# IMM100A register map
Vendor: Infineon; File version: 0.8.0 (Reference Manual v0.8.0)
CPU: CM0 r0p0, little endian, no MPU, no FPU, 2 interrupt priority bits
Registers are 32-bit, read-write, reset 0x0 unless marked. A register's access mark holds for its fields unless they carry their own. Offsets are from the block's base; [hi:lo] are bit positions; {n}, {i} and the like mark numbered series; <NAME> marks a mode.

## SCU_ANALOG — System Control Unit
Base 0x40011000
0x24 ANATSECTRL 16-bit — Temperature Sensor Control Register
  [0] TSE_EN — Temperature sensor enable
    0=Temperature sensor is disabled; 1=Temperature sensor is switched on
0x30 ANATSEIH 16-bit — Temperature Sensor High Temperature Interrupt Register
  [15:0] TSE_IH — Counter value for high temperature interrupt
0x34 ANATSEIL 16-bit reset 0xFFFF — Temperature Sensor Low Temperature Interrupt Register
  [15:0] TSE_IL — Counter value for low temperature interrupt
0x40 ANATSEMON 16-bit ro — Temperature Sensor Counter2 Monitor Register
  [15:0] TSE_MON — Result values; loaded by TSE_DONE
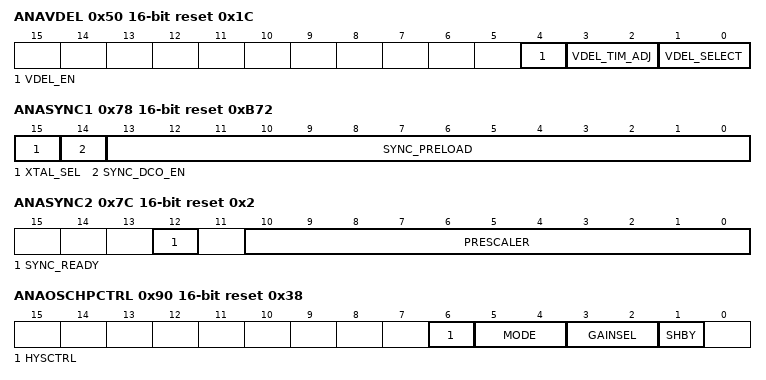
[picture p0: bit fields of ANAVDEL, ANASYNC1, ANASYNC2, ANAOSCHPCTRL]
0x50 ANAVDEL 16-bit reset 0x1C — Voltage Detector Control Register
  [4] VDEL_EN — VDEL unit Enable
    0=VDEL is disabled; 1=VDEL is active
  [3:2] VDEL_TIM_ADJ — VDEL Timing Setting
    0=typ 1us - slowest response time; 1=typ 500n; 2=typ 250n; 3=no delay - fastest response time
  [1:0] VDEL_SELECT — VDEL Range Select
    0=2.25V; 1=3.0V; 2=4.4V
0x6C ANAOFFSET 16-bit reset 0x40 — DCO1 Offset Register
  [6:0] ADJL_OFFSET
    0=- 3.xx%, typ; 63=DCO1 ADJL value is reduced by 1 step (DCO_ADJL - 1); 64=0, DCO_ADJL is not changed, default; 65=DCO1 ADJL value is increased by 1 step (DCO_ADJL + 1); 127=+ 3.xx%, typ
0x78 ANASYNC1 16-bit reset 0xB72 — DCO1 Sync Control Register 1
  [15] XTAL_SEL — Oscillator Source select
    0=OSC_LP is selected; 1=OSC_HP is selected
  [14] SYNC_DCO_EN — DCO1 synchronization feature enable
    0=No DCO1 synchronization via an external clock source. This option is used for the DCO1 calibration using the temperature sensor.; 1=DCO1 gets synchronized via an external clock source
  [13:0] SYNC_PRELOAD — Counter target value, which defines the update cycle
    0x1FFF=Longest integration time = best accuracy
0x7C ANASYNC2 16-bit access per field reset 0x2 — DCO1 Sync Control Register 2
  [12] SYNC_READY ro — DCO1 frequency reached its target value
    0=Actual DCO1 frequency is out of targe; 1=DCO1 is synchronized to the XTAL frequency
  [10:0] PRESCALER rw — Prescaler value
    0=Bypass: Internal sync counter frequency = crystal frequency; 1=DIV1: Internal sync counter feed freq. = crystal frequency/1; 2=DIV2: Internal sync counter feed freq. = crystal frequency/2; 0x7FF=Maximum divider value (for best accuracy, but slowest response)
0x8C ANAOSCLPCTRL 16-bit reset 0x3 — OSC_LP Control Register
  [1:0] MODE — OSC_LP Oscillator Mode
    0=Oscillator is enabled and in operation mode (OSC mode); 1=Oscillator is enabled, shaper is bypassed; 2=Oscillator is in power down mode; 3=Oscillator is in power down mode , Pad can be used in GPIO mode
0x90 ANAOSCHPCTRL 16-bit reset 0x38 — OSC_HP Control Register
  [6] HYSCTRL — Shaper Hystersis Mode
    0=External clock frequency < 20MHz; 1=External clock frequency > 20MHz
  [5:4] MODE — OSC_HP Oscillator Mode
    0=Oscillator is enabled and in active power mode with shaper enabled (OSC mode); 1=Oscillator in power down mode with shaper enabled (External Clock Input Mode); 2=Oscillator is enabled with shaper disabled. No clock output is available unless the shaper is bypass (SHBY=1); 3=Oscillator is in power down mode with shaper disabled. Pad can be used in GPIO mode.
  [3:2] GAINSEL — OSC_HP Oscillator Gain Selection
    0=Gain control is configured for frequencies from 4 MHz to y1 MHz; 1=Gain control is configured for frequencies from 4 MHz to y2 MHz; 2=Gain control is configured for frequencies from 4 MHz to 20 MHz
  [1] SHBY — Shaper Bypass Mode
    0=The shaper is not bypassed; 1=The shaper is bypassed

## CCU40 — Capture Compare Unit 4 - Unit 0
Base 0x48040000
Same registers: CCU41 0x48044000
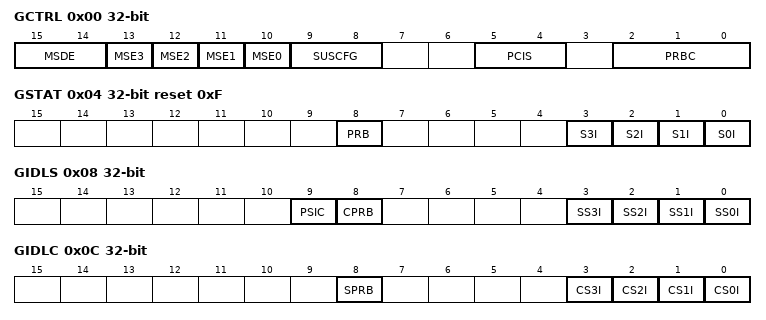
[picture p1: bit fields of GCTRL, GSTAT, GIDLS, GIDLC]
0x00 GCTRL — Global Control Register
  [15:14] MSDE — Multi Channel shadow transfer request configuration
    0=Only the shadow transfer for period and compare values is requested; 1=Shadow transfer for the compare, period and prescaler compare values is requested; 3=Shadow transfer for the compare, period, prescaler and dither compare values is requested
  [n+10] MSE{n} (n=0..3) — Slice {n} Multi Channel shadow transfer enable
    0=Shadow transfer can only be requested by SW; 1=Shadow transfer can be requested via SW and via the CCU4x.MCSS input
  [9:8] SUSCFG — Suspend Mode Configuration
    0=Suspend request ignored. The module never enters in suspend; 1=Stops all the running slices immediately. Safe stop is not applied.; 2=Stops the block immediately and clamps all the outputs to PASSIVE state. Safe stop is applied.; 3=Waits for the roll over of each slice to stop and clamp the slices outputs. Safe stop is applied.
  [5:4] PCIS — Prescaler Input Clock Selection
    0=Module clock; 1=CCU4x.ECLKA; 2=CCU4x.ECLKB; 3=CCU4x.ECLKC
  [2:0] PRBC — Prescaler Clear Configuration
    0=SW only; {v}=GSTATThe register contains the status of the prescaler and each timer slice (idle mode or running)..PRB and prescaler registers are cleared when the Run Bit of CC{v+39} is cleared (v=1..4)
0x04 GSTAT ro reset 0xF — Global Status Register
  [8] PRB — Prescaler Run Bit
    0=Prescaler is stopped; 1=Prescaler is running
  [n] S{n}I (n=0..3) — CC{n+40} IDLE status
    0=Running; 1=Idle
0x08 GIDLS wo — Global Idle Set
  [9] PSIC — Prescaler clear
  [8] CPRB — Prescaler Run Bit Clear
  [n] SS{n}I (n=0..3) — CC{n+40} IDLE mode set
0x0C GIDLC wo — Global Idle Clear
  [8] SPRB — Prescaler Run Bit Set
  [n] CS{n}I (n=0..3) — CC{n+40} IDLE mode clear
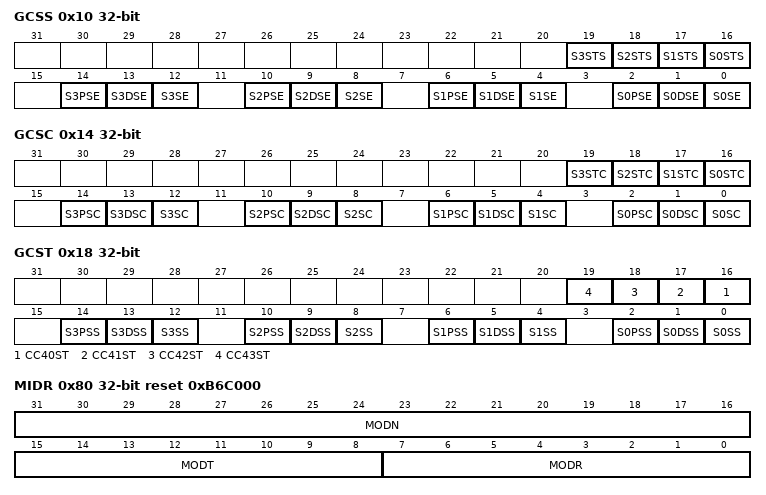
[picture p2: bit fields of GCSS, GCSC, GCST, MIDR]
0x10 GCSS wo — Global Channel Set
  [n+16] S{n}STS (n=0..3) — Slice {n} status bit set
  [4n+2] S{n}PSE (n=0..3) — Slice {n} Prescaler shadow transfer set enable
  [4n+1] S{n}DSE (n=0..3) — Slice {n} Dither shadow transfer set enable
  [4n] S{n}SE (n=0..3) — Slice {n} shadow transfer set enable
0x14 GCSC wo — Global Channel Clear
  [n+16] S{n}STC (n=0..3) — Slice {n} status bit clear
  [4n+2] S{n}PSC (n=0..3) — Slice {n} Prescaler shadow transfer clear
  [4n+1] S{n}DSC (n=0..3) — Slice {n} Dither shadow transfer clear
  [4n] S{n}SC (n=0..3) — Slice {n} shadow transfer clear
0x18 GCST ro — Global Channel Status
  [n-24] CC{n}ST (n=40..43) — Slice {n-40} status bit
  [4n+2] S{n}PSS (n=0..3) — Slice {n} Prescaler shadow transfer status
    0=Prescaler shadow transfer has not been requested; 1=Prescaler shadow transfer has been requested
  [4n+1] S{n}DSS (n=0..3) — Slice {n} Dither shadow transfer status
    0=Dither shadow transfer has not been requested; 1=Dither shadow transfer has been requested
  [4n] S{n}SS (n=0..3) — Slice {n} shadow transfer status
    0=Shadow transfer has not been requested; 1=Shadow transfer has been requested
0x80 MIDR ro reset 0xB6C000 (reset mask 0xFFFFFF00) — Module Identification
  [31:16] MODN — Module Number
  [15:8] MODT — Module Type
  [7:0] MODR — Module Revision
